# PIC32CX2051MTSH128S1 register map
Vendor: Microchip Technology; Series: PIC32CXMTSH; File version: 0
CPU: CM4 r0p1, little endian, MPU, FPU, 4 interrupt priority bits, 96 interrupts
Registers are 32-bit, read-write, reset 0x0 unless marked. A register's access mark holds for its fields unless they carry their own. Offsets are from the block's base; [hi:lo] are bit positions; {n}, {i} and the like mark numbered series.

## ITM — Instrumentation Trace Macrocell
Base 0xE0000000
{0x0+4i} PORT_BYTE_MODE[{i}] (i=0..31) wo — ITM Stimulus Port Registers
  [7:0] PORT — ITM Stimulus Port 8-bit
{0x0+4i} PORT_HWORD_MODE[{i}] (i=0..31) wo (alternate view of PORT_BYTE_MODE[{i}]) — ITM Stimulus Port Registers
  [15:0] PORT — ITM Stimulus Port 16-bit
{0x0+4i} PORT_WORD_MODE[{i}] (i=0..31) wo (alternate view of PORT_BYTE_MODE[{i}]) — ITM Stimulus Port Registers
  [31:0] PORT — ITM Stimulus Port 32-bit
0xE00 TER — ITM Trace Enable Register
0xE40 TPR — ITM Trace Privilege Register
  [3:0] PRIVMASK — Bit mask to enable tracing on ITM stimulus ports
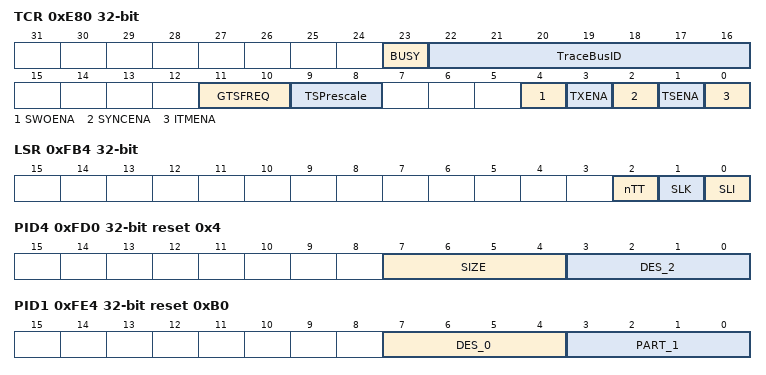
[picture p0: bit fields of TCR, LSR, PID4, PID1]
0xE80 TCR — ITM Trace Control Register
  [23] BUSY — Indicates whether the ITM is currently processing events
  [22:16] TraceBusID — Identifier for multi-source trace stream formatting
  [11:10] GTSFREQ — Global timestamp frequency
  [9:8] TSPrescale — Local timestamp prescaler, used with the trace packet reference clock
  [4] SWOENA — Enables asynchronous clocking of the timestamp counter
  [3] TXENA — Enables forwarding of hardware event packet from the DWT unit to the ITM for output to the TPIU
  [2] SYNCENA — Enables Synchronization packet transmission for a synchronous TPIU
  [1] TSENA — Enables Local timestamp generation
  [0] ITMENA — ITM Enable
0xFB0 LAR wo — FPB Software Lock Access Register
  [31:0] KEY — Lock access control
    0xC5ACCE55=UNLOCK (Unlock key value)
0xFB4 LSR ro — FPB Software Lock Status Register
  [2] nTT — Not thirty-two bit
  [1] SLK — Software Lock status
  [0] SLI — Software Lock implemented
0xFD0 PID4 ro reset 0x4 — FP Peripheral Identification Register 4
  [7:4] SIZE — 4KB count
  [3:0] DES_2 — JEP106 continuation code
{0xFC0+4i} PID{i} ro (i=5..7) — FP Peripheral Identification Register {i}
0xFE0 PID0 ro reset 0x1 — FP Peripheral Identification Register 0
  [7:0] PART_0 — Part number bits[7:0]
0xFE4 PID1 ro reset 0xB0 — FP Peripheral Identification Register 1
  [7:4] DES_0 — JEP106 identification code bits [3:0]
  [3:0] PART_1 — Part number bits[11:8]
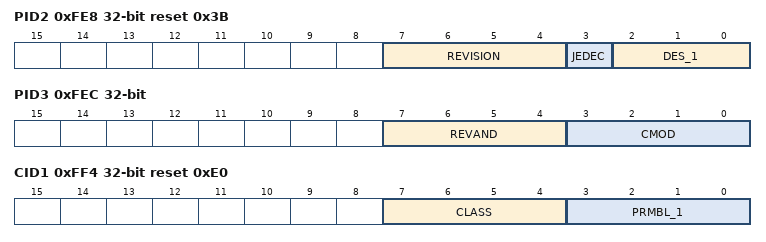
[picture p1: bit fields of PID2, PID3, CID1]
0xFE8 PID2 ro reset 0x3B — FP Peripheral Identification Register 2
  [7:4] REVISION — Component revision
  [3] JEDEC — JEDEC assignee value is used
  [2:0] DES_1 — JEP106 identification code bits[6:4]
0xFEC PID3 ro — FP Peripheral Identification Register 3
  [7:4] REVAND
  [3:0] CMOD — Customer Modified
0xFF0 CID0 ro reset 0xD — FP Component Identification Register 0
  [7:0] PRMBL_0 — CoreSight component identification preamble
0xFF4 CID1 ro reset 0xE0 — FP Component Identification Register 1
  [7:4] CLASS — CoreSight component class
  [3:0] PRMBL_1 — CoreSight component identification preamble
0xFF8 CID2 ro reset 0x5 — FP Component Identification Register 2
  [7:0] PRMBL_2 — CoreSight component identification preamble
0xFFC CID3 ro reset 0xB1 — FP Component Identification Register 3
  [7:0] PRMBL_3 — CoreSight component identification preamble

## MPU — Memory Protection Unit Registers
Base 0xE000ED90
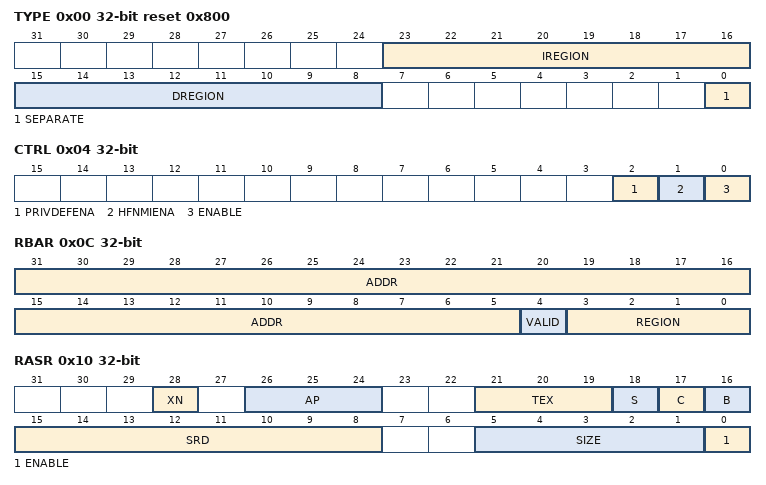
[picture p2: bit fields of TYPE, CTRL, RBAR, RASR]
0x00 TYPE ro reset 0x800 — MPU Type Register
  [23:16] IREGION — Indicates the number of supported MPU instruction regions
  [15:8] DREGION — Indicates the number of supported MPU data regions
  [0] SEPARATE — Indicates support for separate instruction and data address maps
0x04 CTRL — MPU Control Register
  [2] PRIVDEFENA — Enables privileged software access to the default memory map
  [1] HFNMIENA — Enables the operation of MPU during hard fault, NMI, and FAULTMASK handlers
  [0] ENABLE — Enables the MPU
0x08 RNR — MPU Region Number Register
  [7:0] REGION — Indicates the MPU region referenced by the MPU_RBAR and MPU_RASR registers
0x0C RBAR — MPU Region Base Address Register
  [31:5] ADDR — Region base address field
  [4] VALID — MPU Region Number valid bit
  [3:0] REGION — MPU region field
0x10 RASR — MPU Region Attribute and Size Register
  [28] XN — Instruction access disable bit
  [26:24] AP — Access permission field
  [21:19] TEX — MPU access permission attributes
  [18] S — Shareable bit
  [17] C — MPU access permission attributes
  [16] B — MPU access permission attributes
  [15:8] SRD — Subregion disable bits
  [5:1] SIZE — Specifies the size of the MPU protection region
  [0] ENABLE — Region enable bit
{0xC+8i} RBAR_A{i} (i=1..3) — MPU Alias {i} Region Base Address Register
{0x10+8i} RASR_A{i} (i=1..3) — MPU Alias {i} Region Attribute and Size Register

## Notices in the file
Copyright (c) 2025 Microchip Technology Inc.
SPDX-License-Identifier: Apache-2.0
Licensed under the Apache License, Version 2.0 (the "License");
you may not use this file except in compliance with the License.
You may obtain a copy of the License at
http://www.apache.org/licenses/LICENSE-2.0
Unless required by applicable law or agreed to in writing, software
distributed under the License is distributed on an "AS IS" BASIS,
WITHOUT WARRANTIES OR CONDITIONS OF ANY KIND, either express or implied.
See the License for the specific language governing permissions and
limitations under the License.
